# MSS_CTRL register map
Vendor: Texas Instruments
Registers are 32-bit, read-write, no defined reset value unless marked. A register's access mark holds for its fields unless they carry their own. Offsets are as the file gives them; [hi:lo] are bit positions; {n}, {i} and the like mark numbered series; 'fields as' and 'values as' point back to an identical list.

## MSS_CTRL (part 2 of 2)
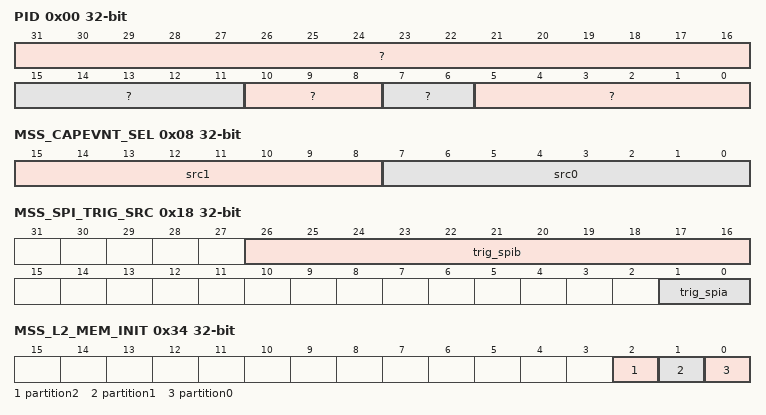
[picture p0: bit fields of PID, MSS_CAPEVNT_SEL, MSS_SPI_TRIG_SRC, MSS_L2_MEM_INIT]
0x00 PID ro
  [31:16] ?, [15:11] ?, [10:8] ?, [7:6] ?, [5:0] ?
0x04 MSS_SW_INT
  [4:0] pulse — Write_pulse bit field: writing 1'b1 to each bit will trigger MSS_SW_INT<0-4> respectively to CR5A/B.
0x08 MSS_CAPEVNT_SEL
  [15:8] src1 — Writing a value 'N' will select Nth interrupt from CR5A/B interrupt mapping to trigger CAP-EVENT1 to all MSS_RTIs. Example: writing 8'h0A will select 10th interrupt to trigger CAP-EVENT1 to all MSS_RTIs. (which is MSS_RTIB_INT1)
  [7:0] src0 — Writing a value 'N' will select Nth interrupt from CR5A/B interrupt mapping to trigger CAP-EVENT0 to all MSS_RTIs. Example: writing 8'h0A will select 10th interrupt to trigger CAP-EVENT0 to all MSS_RTIs. (which is MSS_RTIB_INT1)
0x0C MSS_DMA_REQ_SEL
  [31:0] select — Reserved for R&D. Do not touch
0x10 MSS_DMA1_REQ_SEL
  [31:0] select — Reserved for R&D. Do not touch
0x14 MSS_IRQ_REQ_SEL
  [31:0] select — Reserved for R&D. Do not touch
0x18 MSS_SPI_TRIG_SRC
  [26:16] trig_spib — Writing 1'b1 to each bit will trigger MSS_SPIB Trigger<0-10> respectively
  [1:0] trig_spia — RESERVED:Dont Touch
0x1C MSS_ATCM_MEM_INIT
  [0] mem_init — Write_pulse bit field: Writing 1'b1 will start initializing the ATCM banks of CR5A/B. Value in each row is initialized to 0x0C_0000_0000
0x20 MSS_ATCM_MEM_INIT_DONE
  [0] mem_init_done — This field will be high once initialization of ATCM banks is finished. Writing '1' would clear the bit.
0x24 MSS_ATCM_MEM_INIT_STATUS ro
  [0] mem_status — 1'b0: No initialization is happening for ATCM banks of CR5A/B 1'b1: Initialization is in progress for ATCM banks of CR5A/B
0x28 MSS_BTCM_MEM_INIT
  [0] mem_init — Write_pulse bit field: Writing 1'b1 will start initializing the B0/1TCM banks of CR5A/B
0x2C MSS_BTCM_MEM_INIT_DONE
  [0] mem_init_done — This field will be high once initialization of B0/1TCM banks is finished. Writing '1' would clear the bit.
0x30 MSS_BTCM_MEM_INIT_STATUS ro
  [0] mem_status — 1'b0: No initialization is happening for B0/1TCM banks of CR5A/B 1'b1: Initialization is in progress for B0/1TCM banks of CR5A/B
0x34 MSS_L2_MEM_INIT
  [2] partition2 — Write_pulse bit field: Writing 1'b1 will start initializing the L2 Bank2. Value in each row is initialized to 0x0
  [1] partition1 — Write_pulse bit field: Writing 1'b1 will start initializing the L2 Bank1. Value in each row is initialized to 0x0
  [0] partition0 — Write_pulse bit field: Writing 1'b1 will start initializing the L2 Bank0. Value in each row is initialized to 0x0
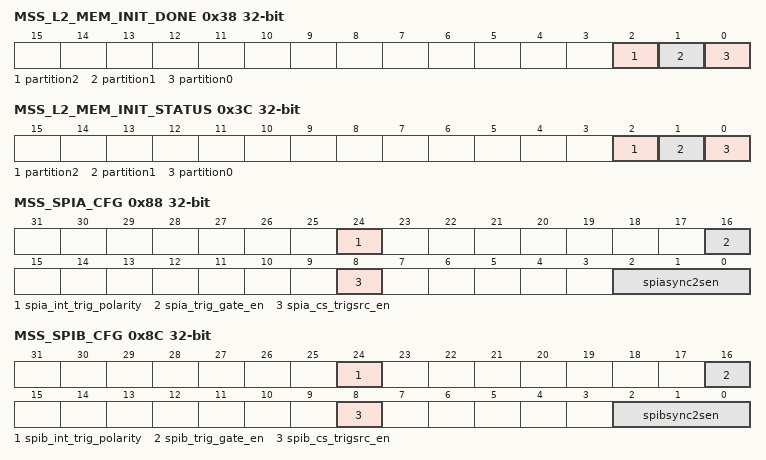
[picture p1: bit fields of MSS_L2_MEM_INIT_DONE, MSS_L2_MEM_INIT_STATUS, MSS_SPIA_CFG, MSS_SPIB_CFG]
0x38 MSS_L2_MEM_INIT_DONE
  [2] partition2 — This field will be high once intialization of L2 bank2 is finished. Writing '1' would clear the bit
  [1] partition1 — This field will be high once intialization of L2 bank1 is finished. Writing '1' would clear the bit
  [0] partition0 — This field will be high once intialization of L2 bank0 is finished. Writing '1' would clear the bit
0x3C MSS_L2_MEM_INIT_STATUS ro
  [2] partition2 — 1'b0: No initialization is happening for L2 bank2 1'b1: Initialization is in progress for L2 bank2
  [1] partition1 — 1'b0: No initialization is happening for L2 bank1 1'b1: Initialization is in progress for L2 bank1
  [0] partition0 — 1'b0: No initialization is happening for L2 bank0 1'b1: Initialization is in progress for L2 bank0
0x40 MSS_MAILBOX_MEM_INIT
  [0] mem0_init — Write_pulse bit field: Writing 1'b1 will start initializing the MSS_MBOX. Value in each row is initialized to 0x0
0x44 MSS_MAIlBOX_MEM_INIT_DONE
  [0] mem0_done — This field will be high once intialization of MSS_MBOX is finished. Writing '1' would clear the bit
0x48 MSS_MAILBOX_MEM_INIT_STATUS ro
  [0] mem0_status — 1'b0: No initialization is happening for MSS_MBOX 1'b1: Initialization is in progress for MSS_MBOX
0x4C MSS_RETRAM_MEM_INIT
  [0] mem0_init — Write_pulse bit field: Writing 1'b1 will start initializing the MSS_RETRAM. Value in each row is initialized to 0x0
0x50 MSS_RETRAM_MEM_INIT_DONE
  [0] mem0_done — This field will be high once intialization of MSS_RETRAM is finished. Writing '1' would clear the bit
0x54 MSS_RETRAM_MEM_INIT_STATUS ro
  [0] mem0_status — 1'b0: No initialization is happening for MSS_RETRAM 1'b1: Initialization is in progress for MSS_RETRAM
0x58 MSS_SPIA_MEM_INIT
  [0] mem0_init — RESERVED:Dont Touch
0x5C MSS_SPIA_MEM_INIT_DONE
  [0] mem0_done — RESERVED: Dont Use
0x60 MSS_SPIA_MEM_INIT_STATUS ro
  [0] mem0_status — RESERVED: Dont Use
0x64 MSS_SPIB_MEM_INIT
  [0] mem0_init — Write_pulse bit field: Writing 1'b1 will start initializing the MSS_SPIB. Value in each row is initialized to 0x0
0x68 MSS_SPIB_MEM_INIT_DONE
  [0] mem0_done — This field will be high once intialization of MSS_SPIB is finished. Writing '1' would clear the bit
0x6C MSS_SPIB_MEM_INIT_STATUS ro
  [0] mem0_status — 1'b0: No initialization is happening for MSS_SPIB 1'b1: Initialization is in progress for MSS_SPIB
0x70 MSS_TPCC_MEMINIT_START
  [0] tpcc_a_meminit_start — Write_pulse bit field: Writing 1'b1 will start initializing the MSS_TPCCA
0x74 MSS_TPCC_MEMINIT_DONE
  [0] tpcc_a_meminit_done — This field will be high once intialization of MSS_TPCCA is finished. Writing '1' would clear the bit
0x78 MSS_TPCC_MEMINIT_STATUS ro
  [0] tpcc_a_meminit_status — 1'b0: No initialization is happening for MSS_TPCCA 1'b1: Initialization is in progress for MSS_TPCCB
0x7C MSS_GPADC_MEM_INIT
  [0] mem0_init — Write_pulse bit field: Writing 1'b1 will start initializing the MSS_GPADC_DATA_MEM. Value in each row is initialized to 0x00_0000_03FF
0x80 MSS_GPADC_MEM_INIT_DONE
  [0] mem0_done — This field will be high once intialization of MSS_GPADC_DATA_MEM is finished. Writing '1' would clear the bit
0x84 MSS_GPADC_MEM_INIT_STATUS ro
  [0] mem0_status — 1'b0: No initialization is happening for MSS_GPADC_DATA_MEM 1'b1: Initialization is in progress for MSS_GPADC_DATA_MEM
0x88 MSS_SPIA_CFG — RESERVED: Dont Use
  [24] spia_int_trig_polarity — RESERVED:Dont Use
  [16] spia_trig_gate_en — RESERVED:Dont Use
  [8] spia_cs_trigsrc_en — RESERVED:Dont Use
  [2:0] spiasync2sen — RESERVED:Dont Use
0x8C MSS_SPIB_CFG
  [24] spib_int_trig_polarity — SPIB trigger source polarity select. 0 - Polarity 0, 1 -Polarity 1
  [16] spib_trig_gate_en — When set the TRIGGER s are un-gated only when chip-select is active
  [8] spib_cs_trigsrc_en — MIBSPIB CS Trigger SRC enable 1 : Use CS as trigger source
  [2:0] spibsync2sen — Donot touch the field. Used as Tie-off for IP-config.
0x90 MSS_EPWM_CFG
  [31:0] epwm_config — bit0: SW syncin for EPWM1 bit1: SW syncin for EPWM2 bit2: SW syncin for EPWM3 bit8:9 : select bits for EPWM1 '0' : external syncin '1' : reserved '2' : sw syncin '3' : reserved bit10:11 : select bits for EPWM2 '0' : external syncin '1' : chained from EPWM1 '2' : sw syncin '3' : reserved bit12:13 : select bits for EPWM3 '0' : external syncin '1' : chained from EPWM2 '2' : sw syncin '3' : reserved bit24:TBCLKEN for EPWM1 bit25:TBCLKEN for EPWM2 bit26:TBCLKEN for EPWM3
0x94 MSS_GIO_CFG
  [31:0] gio_config — bit0 : writing '1' will slect negedge for pulse generation of GIO_PAD_INT0 to IRQ bit1 : writing '1' will slect negedge for pulse generation of GIO_PAD_INT1to IRQ bit2: writing '1' will slect negedge for pulse generation of GIO_PAD_INT2 to IRQ bit3 : writing '1' will slect negedge for pulse generation of GIO_PAD_INT3 to IRQ bit4 : writing '1' will slect negedge for pulse generation of GIO_PAD_INT4 to IRQ bit5 : writing '1' will slect negedge for pulse generation of GIO_PAD_INT5 to IRQ bit6 : writing '1' will slect negedge for pulse generation of GIO_PAD_INT6 to IRQ bit7 : writing '1' will slect negedge for pulse generation of GIO_PAD_INT7 to IRQ
0x9C HW_SPARE_REG1
  [31:0] NU — Resereved for R&D
0xAC HW_SPARE_REG2
  [31:0] NU — Resereved for R&D
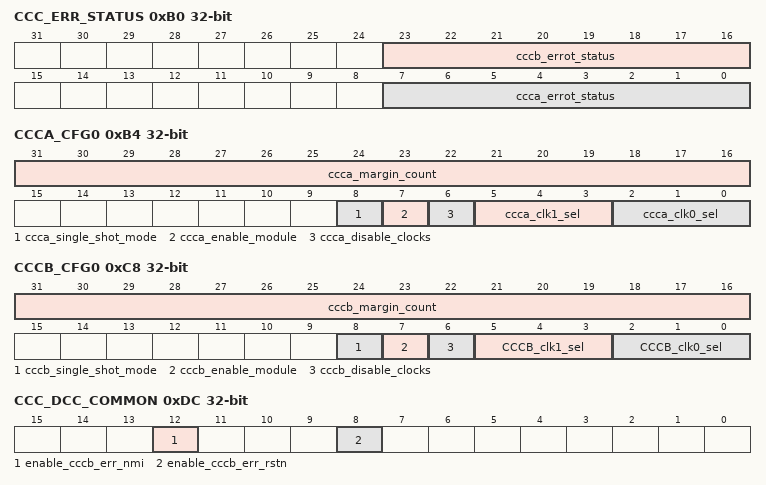
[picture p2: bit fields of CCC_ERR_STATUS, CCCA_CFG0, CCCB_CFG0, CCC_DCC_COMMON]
0xB0 CCC_ERR_STATUS ro
  [23:16] cccb_errot_status — CCCB Error Status (for Debug) {3'd0, counter_error, counter_done, timeout_error, counter_error, counter_done}
  [7:0] ccca_errot_status — CCCA Error Status (for Debug) {3'd0, counter_error, counter_done, timeout_error, counter_error, counter_done}
0xB4 CCCA_CFG0
  [31:16] ccca_margin_count — Margin value for clock comparison in terms of counter1 clock.CCC error will not be generated if counter1 counter value is within count1_expected_val +/- MARGIN_COUNT
  [8] ccca_single_shot_mode — 1: Single shot mode 0: Continuous mode
  [7] ccca_enable_module — 1'b1: Enables CCCA 1'b0: Disables CCCA
  [6] ccca_disable_clocks — 1: Clock gated to counter0 and counter1 0: Normal mode
  [5:3] ccca_clk1_sel — Selection for Clock 1 0: Select clock0_src0 as source for counter1 1: Select clock0_src1 as source for counter1 2: Select clock0_src2 as source for counter1 ... 7: Select clock0_src7 as source for counter1
  [2:0] ccca_clk0_sel — Selection for Clock 0 0: Select clock0_src0 as source for counter0 1: Select clock0_src1 as source for counter0 2: Select clock0_src2 as source for counter0 ... 7: Select clock0_src7 as source for counter0
0xB8 CCCA_CFG1
  [31:0] ccca_cfg — count0_expiry_val Counter 1 is compared for count1_expected_val +/- MARGIN_COUNT when counter0 expires after counting down from count0_expiry_val to 0
0xBC CCCA_CFG2
  [31:0] ccca_cfg — count1_expected_val Expected value of counter 1 when counter 0 expires after counting down from count0_expiry value
0xC0 CCCA_CFG3
  [31:0] ccca_cfg — Timeout Error Counter value in counter1 clock
0xC4 CCCA_CNTVAL ro
  [31:0] ccca_cfg — count1_val_out Real time value of counter1
0xC8 CCCB_CFG0
  [31:16] cccb_margin_count — Margin value for clock comparison in terms of counter1 clock.CCC error will not be generated if counter1 counter value is within count1_expected_val +/- MARGIN_COUNT
  [8] cccb_single_shot_mode — 1: Single shot mode 0: Continuous mode
  [7] cccb_enable_module — 1'b1: Enables CCCB 1'b0: Disables CCCB
  [6] cccb_disable_clocks — 1: Clock gated to counter0 and counter1 0: Normal mode
  [5:3] CCCB_clk1_sel — Selection for Clock 1 0: Select clock0_src0 as source for counter1 1: Select clock0_src1 as source for counter1 2: Select clock0_src2 as source for counter1 ... 7: Select clock0_src7 as source for counter1
  [2:0] CCCB_clk0_sel — Selection for Clock 0 0: Select clock0_src0 as source for counter0 1: Select clock0_src1 as source for counter0 2: Select clock0_src2 as source for counter0 ... 7: Select clock0_src7 as source for counter0
0xCC CCCB_CFG1
  [31:0] cccb_cfg — count0_expiry_val Counter 1 is compared for count1_expected_val +/- MARGIN_COUNT when counter0 expires after counting down from count0_expiry_val to 0
0xD0 CCCB_CFG2
  [31:0] cccb_cfg — count1_expected_val Expected value of counter 1 when counter 0 expires after counting down from count0_expiry value
0xD4 CCCB_CFG3
  [31:0] cccb_cfg — Timeout Error Counter value in counter1 clock
0xD8 CCCB_CNTVAL ro
  [31:0] cccb_cfg — count1_val_out Real time value of counter1
0xDC CCC_DCC_COMMON
  [12] enable_cccb_err_nmi — 1'b0:Enable CCCB error to generate NMI. 1'b1:disables CCCB error to generate NMI.
  [8] enable_cccb_err_rstn — 1'b0: Enable CCCB error to generate WD restn. 1'b1: disables CCCB error to generate WD restn.
0xE0 R5_GLOBAL_CONFIG
  [0] teinit — Exception handling state at reset. 0-ARM 1-Thumb
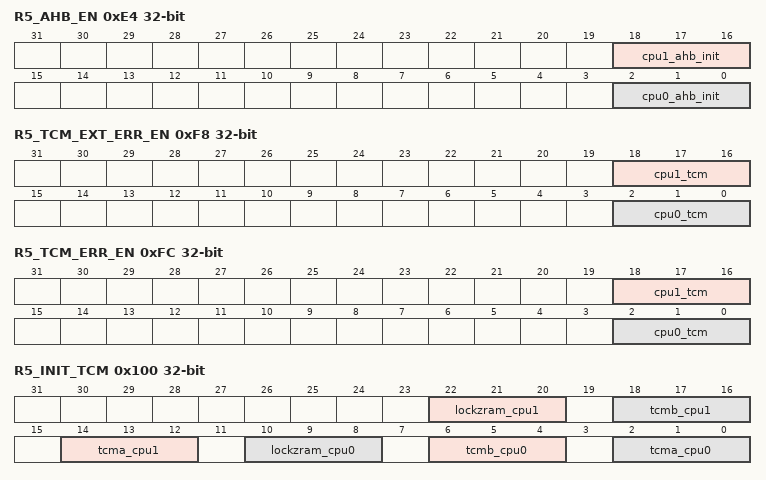
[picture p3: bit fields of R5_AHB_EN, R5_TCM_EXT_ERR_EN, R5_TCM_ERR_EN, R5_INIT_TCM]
0xE4 R5_AHB_EN
  [18:16] cpu1_ahb_init — Ti internal Register. Modifying this register is not recommended Signal decides whehter ahb interface is enabled or not.
  [2:0] cpu0_ahb_init — Ti internal Register. Modifying this register is not recommended Signal decides whehter ahb interface is enabled or not.
0xE8 R5A_AHB_BASE
  [19:0] ahb_base — Ti internal Register. Modifying this register is not recommended Decides the base address of ahb region
0xEC R5A_AHB_SIZE
  [4:0] ahb_size — Ti internal Register. Modifying this register is not recommended Code for selecting size for ahb. b00011 4KB b00100 8KB b00101 16KB b00110 32KB b00111 64KB b01000 128KB b01001 256KB b01010 512KB b01011 1MB b01100 2MB b01101 4MB b01110 8MB b01111 16MB b10000 32MB b10001 64MB b10010 128MB b10011 256MB b10100 512MB b10101 1GB b10110 2GB b10111 4GB
0xF0 R5B_AHB_BASE
  fields as R5A_AHB_BASE
0xF4 R5B_AHB_SIZE
  fields as R5A_AHB_SIZE
0xF8 R5_TCM_EXT_ERR_EN
  [18:16] cpu1_tcm — Ti internal Register. Modifying this register is not recommended TCMs external error enable. Tie each bit high to enable the external error signal for each TCM at reset
  [2:0] cpu0_tcm — Ti internal Register. Modifying this register is not recommended TCMs external error enable. Tie each bit high to enable the external error signal for each TCM at reset
0xFC R5_TCM_ERR_EN
  [18:16] cpu1_tcm — Ti internal Register. Modifying this register is not recommended TCMs ECC check enable. Tie each bit high to enable ECC checking on appropraite TCM
  [2:0] cpu0_tcm — Ti internal Register. Modifying this register is not recommended TCMs ECC check enable. Tie each bit high to enable ECC checking on appropraite TCM
0x100 R5_INIT_TCM
  [22:20] lockzram_cpu1 — Ti internal Register. Modifying this register is not recommended When HIGH ATCM base address at reset is 0x0 when LOW BTCM base address at reset is 0x0
  [18:16] tcmb_cpu1 — Ti internal Register. Modifying this register is not recommended When HIGH enables BTCM interface out of reset
  [14:12] tcma_cpu1 — Ti internal Register. Modifying this register is not recommended When HIGH enables ATCM interface out of reset
  [10:8] lockzram_cpu0 — Ti internal Register. Modifying this register is not recommended When HIGH ATCM base address at reset is 0x0 when LOW BTCM base address at reset is 0x0
  [6:4] tcmb_cpu0 — Ti internal Register. Modifying this register is not recommended When HIGH enables BTCM interface out of reset
  [2:0] tcma_cpu0 — Ti internal Register. Modifying this register is not recommended When HIGH enables ATCM interface out of reset
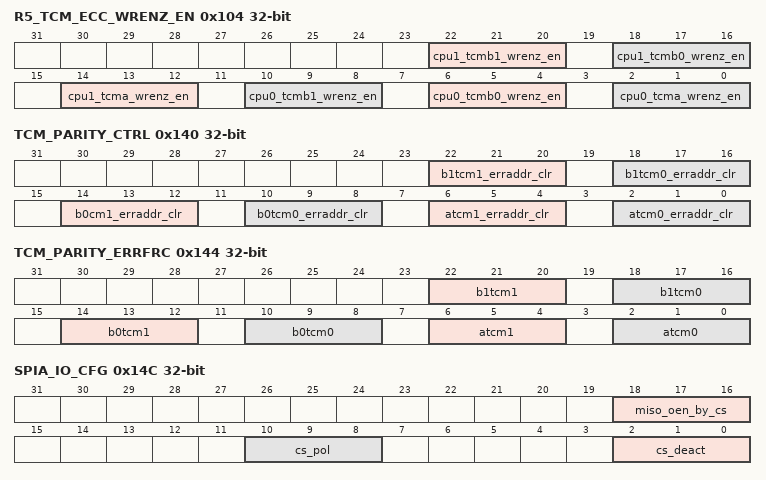
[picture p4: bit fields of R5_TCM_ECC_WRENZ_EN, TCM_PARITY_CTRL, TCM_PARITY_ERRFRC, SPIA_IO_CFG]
0x104 R5_TCM_ECC_WRENZ_EN
  [22:20] cpu1_tcmb1_wrenz_en — RESERVED: Dont Use
  [18:16] cpu1_tcmb0_wrenz_en — RESERVED: Dont Use
  [14:12] cpu1_tcma_wrenz_en — RESERVED: Dont Use
  [10:8] cpu0_tcmb1_wrenz_en — writing '000' blocks the writes to ECC-bits of TCMB0-RAM of CR5A. Writing '111' unblocks the writes to ECC-bits of TCMB1-RAM of CR5A
  [6:4] cpu0_tcmb0_wrenz_en — writing '000' blocks the writes to ECC-bits of TCMB0-RAM of CR5A. Writing '111' unblocks the writes to ECC-bits of TCMB0-RAM of CR5A
  [2:0] cpu0_tcma_wrenz_en — writing '000' blocks the writes to ECC-bits of TCMA-RAM of CR5A. Writing '111' unblocks the writes to ECC-bits of TCMA-RAM of CR5A
{0x108+4i} ESM_GATING{i} (i=0..3)
  [31:0] esm_gating — bit3:0 : writing '000' will ungate the ESM_GRP2_ERROR_{8i} bit7:4 : writing '000' will ungate the ESM_GRP2_ERROR_{8i+1} bit31:28 : writing '000' will ungate the ESM_GRP2_ERROR_{8i+7}
{0x108+4i} ESM_GATING{i} (i=4..7)
  [31:0] esm_gating — bit3:0 : writing '000' will ungate the ESM_GRP3_ERROR_{8i-32} bit7:4 : writing '000' will ungate the ESM_GRP3_ERROR_{8i-31} bit31:28 : writing '000' will ungate the ESM_GRP3_ERROR_{8i-25}
0x128 ERR_PARITY_ATCM0 ro
  [19:0] addr — Address lathched when parity error is occurred for ATCM of CR5A
0x12C ERR_PARITY_ATCM1 ro
  [19:0] addr — RESERVED: Dont Use
0x130 ERR_PARITY_B0TCM0 ro
  [19:0] addr — Address lathched when parity error is occurred for B0TCM of CR5A
0x134 ERR_PARITY_B0TCM1 ro
  [19:0] addr — RESERVED: Dont Use
0x138 ERR_PARITY_B1TCM0 ro
  [19:0] addr — Address lathched when parity error is occurred for B1TCM of CR5A
0x13C ERR_PARITY_B1TCM1 ro
  [19:0] addr — RESERVED: Dont Use
0x140 TCM_PARITY_CTRL
  [22:20] b1tcm1_erraddr_clr — RESERVED: Dont Use
  [18:16] b1tcm0_erraddr_clr — Write pulse bit field: writing 3'b111 clears the Address latched after parity error for B1TCM of CR5A
  [14:12] b0cm1_erraddr_clr — RESERVED: Dont Use
  [10:8] b0tcm0_erraddr_clr — RESERVED: Dont Use
  [6:4] atcm1_erraddr_clr — RESERVED: Dont Use
  [2:0] atcm0_erraddr_clr — Pulse bit-field writing 3'b111 clears the Address latched after parity error for ATCM of CR5A
0x144 TCM_PARITY_ERRFRC
  [22:20] b1tcm1 — RESERVED: Dont Use
  [18:16] b1tcm0 — Write pulse bit field: writing 3'b111 forces a parity error for B1TCM of CR5A
  [14:12] b0tcm1 — RESERVED: Dont Use
  [10:8] b0tcm0 — Write pulse bit field: writing 3'b111 forces a parity error for B0TCM of CR5A
  [6:4] atcm1 — RESERVED: Dont Use
  [2:0] atcm0 — Write pulse bit field: writing 3'b111 forces a parity error for ATCM of CR5A
0x148 HW_SPARE_REG3
  [31:0] NU — Resereved for R&D
0x14C SPIA_IO_CFG
  [18:16] miso_oen_by_cs — RESERVED:Dont Use
  [10:8] cs_pol — RESERVED:Dont Use
  [2:0] cs_deact — RESERVED:Dont Use
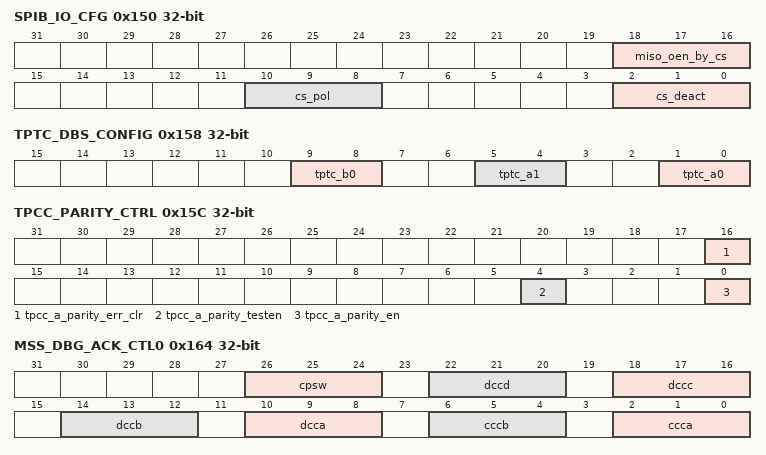
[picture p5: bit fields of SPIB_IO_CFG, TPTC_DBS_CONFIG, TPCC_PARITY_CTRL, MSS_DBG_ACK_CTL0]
0x150 SPIB_IO_CFG
  [18:16] miso_oen_by_cs — MIBSPIB MISO OE_N Control based on Chip selectCS-applicable in slave mode 1:MISO OEN controlled based on CS.When CS is inactive OE_N=1 0:MISO OEN controlled by IP
  [10:8] cs_pol — MIBSPIB CS polarity-slave mode 1: Active high 0:Active low
  [2:0] cs_deact — 1 : MIBSPIB External chip select is overridden with the value of MIBSPIB CS polarity-slave mode
0x154 SPI_HOST_IRQ
  [2:0] host_irq
0x158 TPTC_DBS_CONFIG
  [9:8] tptc_b0 — Default burst size tieoff value for TPTC_B0
  [5:4] tptc_a1 — Default burst size tieoff value for TPTC_A1
  [1:0] tptc_a0 — Default burst size tieoff value for TPTC_A0
0x15C TPCC_PARITY_CTRL
  [16] tpcc_a_parity_err_clr — Write pulse bit field: parity clear bit. Writing 1'b1 will clear the tpcc_a_parity_addr
  [4] tpcc_a_parity_testen — parity test enable for tpcc a
  [0] tpcc_a_parity_en — writing 1'b1 enables parity for TPCC_A
0x160 TPCC_PARITY_STATUS ro
  [7:0] tpcc_a_parity_addr — address where parity error happened for tpcca
0x164 MSS_DBG_ACK_CTL0
  [26:24] cpsw — Enable Suspend control for the peripheral. 0 :Peripheral not suspended along with processor 1: Peripehal Suspended along with procesor
  [22:20] dccd — Enable Suspend control for the peripheral. 0 :Peripheral not suspended along with processor 1: Peripehal Suspended along with procesor
  [18:16] dccc — Enable Suspend control for the peripheral. 0 :Peripheral not suspended along with processor 1: Peripehal Suspended along with procesor
  [14:12] dccb — Enable Suspend control for the peripheral. 0 :Peripheral not suspended along with processor 1: Peripehal Suspended along with procesor
  [10:8] dcca — Enable Suspend control for the peripheral. 0 :Peripheral not suspended along with processor 1: Peripehal Suspended along with procesor
  [6:4] cccb — Enable Suspend control for the peripheral. 0 :Peripheral not suspended along with processor 1: Peripehal Suspended along with procesor
  [2:0] ccca — Enable Suspend control for the peripheral. 0 :Peripheral not suspended along with processor 1: Peripehal Suspended along with procesor
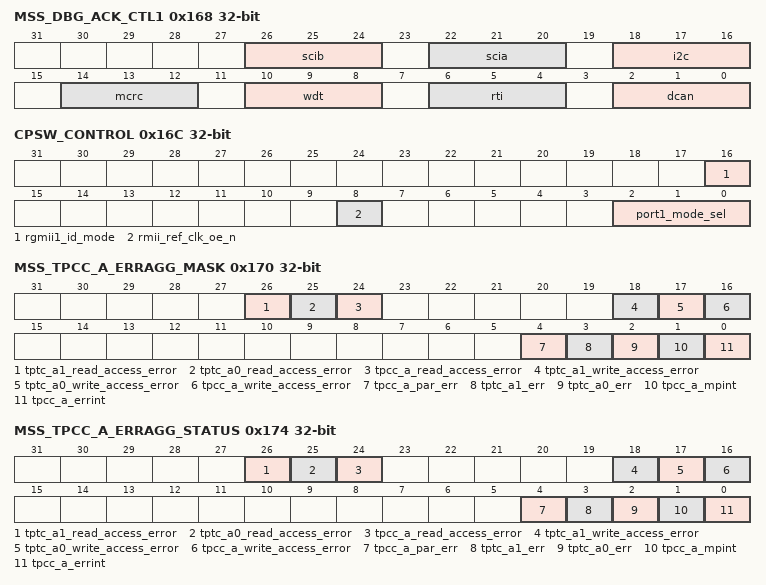
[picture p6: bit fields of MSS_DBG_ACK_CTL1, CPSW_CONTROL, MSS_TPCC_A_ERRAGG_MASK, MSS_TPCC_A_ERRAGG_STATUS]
0x168 MSS_DBG_ACK_CTL1
  [26:24] scib — Enable Suspend control for the peripheral. 0 :Peripheral not suspended along with processor 1: Peripehal Suspended along with procesor
  [22:20] scia — Enable Suspend control for the peripheral. 0 :Peripheral not suspended along with processor 1: Peripehal Suspended along with procesor
  [18:16] i2c — Enable Suspend control for the peripheral. 0 :Peripheral not suspended along with processor 1: Peripehal Suspended along with procesor
  [14:12] mcrc — Enable Suspend control for the peripheral. 0 :Peripheral not suspended along with processor 1: Peripehal Suspended along with procesor
  [10:8] wdt — Enable Suspend control for the peripheral. 0 :Peripheral not suspended along with processor 1: Peripehal Suspended along with procesor
  [6:4] rti — Enable Suspend control for the peripheral. 0 :Peripheral not suspended along with processor 1: Peripehal Suspended along with procesor
  [2:0] dcan — Enable Suspend control for the peripheral. 0 :Peripheral not suspended along with processor 1: Peripehal Suspended along with procesor
0x16C CPSW_CONTROL
  [16] rgmii1_id_mode — writing 1'b1 would disable the internal clock delays. And those delays need to be handled on board.
  [8] rmii_ref_clk_oe_n — To select the rmii_ref_clk from PAD or from MSS_RCM. 0: clock will be from mss_rcm through IO internal loopback 1: will be from
  [2:0] port1_mode_sel — Port 1 Interface 00 = GMII/MII 01 = RMII 10 = RGMII 11 = Not Supported
0x170 MSS_TPCC_A_ERRAGG_MASK
  [26] tptc_a1_read_access_error — Mask Error from MSS_TPTC_A1 to aggregated Error MSS_TPCC_A_ERRAGG 1 : Error is Masked 0 : Error is Unmasked
  [25] tptc_a0_read_access_error — Mask Error from MSS_TPTC_A0 to aggregated Error MSS_TPCC_A_ERRAGG 1 : Error is Masked 0 : Error is Unmasked
  [24] tpcc_a_read_access_error — Mask Error from MSS_TPCC_A to aggregated Error MSS_TPCC_A_ERRAGG 1 : Error is Masked 0 : Error is Unmasked
  [18] tptc_a1_write_access_error — Mask Error from MSS_TPTC_A1 to aggregated Error MSS_TPCC_A_ERRAGG 1 : Error is Masked 0 : Error is Unmasked
  [17] tptc_a0_write_access_error — Mask Error from MSS_TPTC_A0 to aggregated Error MSS_TPCC_A_ERRAGG 1 : Error is Masked 0 : Error is Unmasked
  [16] tpcc_a_write_access_error — Mask Error from MSS_TPCC_A to aggregated Error MSS_TPCC_A_ERRAGG 1 : Error is Masked 0 : Error is Unmasked
  [4] tpcc_a_par_err — Mask Error from MSS_TPCC_A to aggregated Error MSS_TPCC_A_ERRAGG 1 : Error is Masked 0 : Error is Unmasked
  [3] tptc_a1_err — Mask Error from MSS_TPTC_A1 to aggregated Error MSS_TPCC_A_ERRAGG 1 : Error is Masked 0 : Error is Unmasked
  [2] tptc_a0_err — Mask Error from MSS_TPTC_A0 to aggregated Error MSS_TPCC_A_ERRAGG 1 : Error is Masked 0 : Error is Unmasked
  [1] tpcc_a_mpint — Mask Error from MSS_TPCC_A to aggregated Error MSS_TPCC_A_ERRAGG 1 : Error is Masked 0 : Error is Unmasked
  [0] tpcc_a_errint — Mask Error from MSS_TPCC_A to aggregated Error MSS_TPCC_A_ERRAGG 1 : Error is Masked 0 : Error is Unmasked
0x174 MSS_TPCC_A_ERRAGG_STATUS
  [26] tptc_a1_read_access_error — Status of Error from MSS_TPTC_A1. Set only if Interupt is unmasked in MSS_TPCC_A_ERRAGG_MASK Wrie 0x1 to clear this Error.
  [25] tptc_a0_read_access_error — Status of Error from MSS_TPTC_A0. Set only if Interupt is unmasked in MSS_TPCC_A_ERRAGG_MASK Wrie 0x1 to clear this Error.
  [24] tpcc_a_read_access_error — Status of Error from MSS_TPCC_A. Set only if Interupt is unmasked in MSS_TPCC_A_ERRAGG_MASK Wrie 0x1 to clear this Error.
  [18] tptc_a1_write_access_error — Status of Error from MSS_TPTC_A1. Set only if Interupt is unmasked in MSS_TPCC_A_ERRAGG_MASK Wrie 0x1 to clear this Error.
  [17] tptc_a0_write_access_error — Status of Error from MSS_TPTC_A0. Set only if Interupt is unmasked in MSS_TPCC_A_ERRAGG_MASK Wrie 0x1 to clear this Error.
  [16] tpcc_a_write_access_error — Status of Error from MSS_TPCC_A. Set only if Interupt is unmasked in MSS_TPCC_A_ERRAGG_MASK Wrie 0x1 to clear this Error.
  [4] tpcc_a_par_err — Status of Error from MSS_TPCC_A. Set only if Interupt is unmasked in MSS_TPCC_A_ERRAGG_MASK Wrie 0x1 to clear this Error.
  [3] tptc_a1_err — Status of Error from MSS_TPTC_A1. Set only if Interupt is unmasked in MSS_TPCC_A_ERRAGG_MASK Wrie 0x1 to clear this Error.
  [2] tptc_a0_err — Status of Error from MSS_TPTC_A0. Set only if Interupt is unmasked in MSS_TPCC_A_ERRAGG_MASK Wrie 0x1 to clear this Error.
  [1] tpcc_a_mpint — Status of Error from MSS_TPCC_A. Set only if Interupt is unmasked in MSS_TPCC_A_ERRAGG_MASK Wrie 0x1 to clear this Error.
  [0] tpcc_a_errint — Status of Error from MSS_TPCC_A. Set only if Interupt is unmasked in MSS_TPCC_A_ERRAGG_MASK Wrie 0x1 to clear this Error.
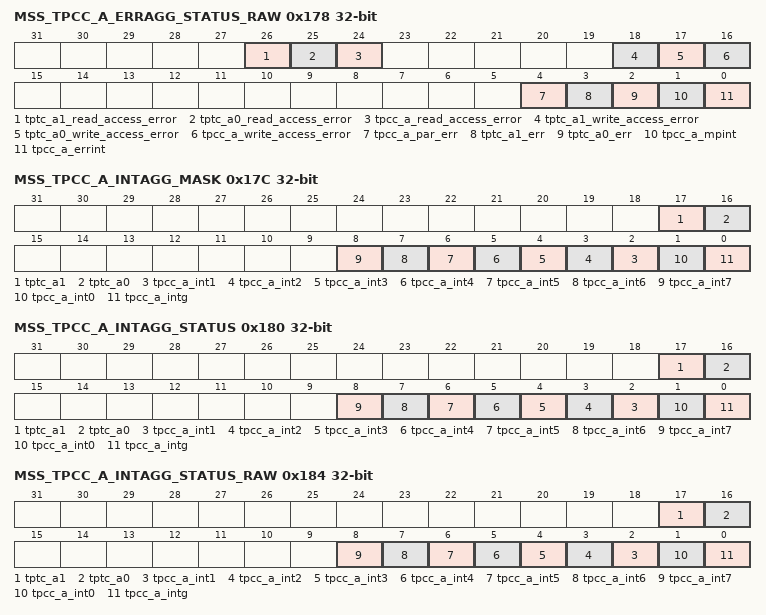
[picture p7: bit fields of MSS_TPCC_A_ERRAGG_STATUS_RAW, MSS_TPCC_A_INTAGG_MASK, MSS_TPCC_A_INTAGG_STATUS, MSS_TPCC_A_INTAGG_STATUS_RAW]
0x178 MSS_TPCC_A_ERRAGG_STATUS_RAW
  [26] tptc_a1_read_access_error — Raw Status of Error from MSS_TPTC_A1. Set irrespective if the Interupt is masked or unmasked in MSS_TPCC_A_ERRAGG_MASK
  [25] tptc_a0_read_access_error — Raw Status of Error from MSS_TPTC_A0. Set irrespective if the Interupt is masked or unmasked in MSS_TPCC_A_ERRAGG_MASK
  [24] tpcc_a_read_access_error — Raw Status of Error from MSS_TPCC_A. Set irrespective if the Interupt is masked or unmasked in MSS_TPCC_A_ERRAGG_MASK
  [18] tptc_a1_write_access_error — Raw Status of Error from MSS_TPTC_A1. Set irrespective if the Interupt is masked or unmasked in MSS_TPCC_A_ERRAGG_MASK
  [17] tptc_a0_write_access_error — Raw Status of Error from MSS_TPTC_A0. Set irrespective if the Interupt is masked or unmasked in MSS_TPCC_A_ERRAGG_MASK
  [16] tpcc_a_write_access_error — Raw Status of Error from MSS_TPCC_A. Set irrespective if the Interupt is masked or unmasked in MSS_TPCC_A_ERRAGG_MASK
  [4] tpcc_a_par_err — Raw Status of Error from MSS_TPCC_A. Set irrespective if the Interupt is masked or unmasked in MSS_TPCC_A_ERRAGG_MASK
  [3] tptc_a1_err — Raw Status of Error from MSS_TPTC_A1. Set irrespective if the Interupt is masked or unmasked in MSS_TPCC_A_ERRAGG_MASK
  [2] tptc_a0_err — Raw Status of Error from MSS_TPTC_A0. Set irrespective if the Interupt is masked or unmasked in MSS_TPCC_A_ERRAGG_MASK
  [1] tpcc_a_mpint — Raw Status of Error from MSS_TPCC_A. Set irrespective if the Interupt is masked or unmasked in MSS_TPCC_A_ERRAGG_MASK
  [0] tpcc_a_errint — Raw Status of Error from MSS_TPCC_A. Set irrespective if the Interupt is masked or unmasked in MSS_TPCC_A_ERRAGG_MASK
0x17C MSS_TPCC_A_INTAGG_MASK
  [17] tptc_a1 — Mask Interrupt from TPTC A1 to aggregated Interrupt MSS_TPCC_A_INTAGG 1 : Interrupt is Masked 0 : Interrupt is Unmasked
  [16] tptc_a0 — Mask Interrupt from TPTC A0 to aggregated Interrupt MSS_TPCC_A_INTAGG 1 : Interrupt is Masked 0 : Interrupt is Unmasked
  [n+1] tpcc_a_int{n} (n=1..7) — Mask Interrupt from MSS_TPCC_A to aggregated Interrupt MSS_TPCC_A_INTAGG 1 : Interrupt is Masked 0 : Interrupt is Unmasked
  [1] tpcc_a_int0 — Mask Interrupt from TPCC A to aggregated Interrupt MSS_TPCC_A_INTAGG 1 : Interrupt is Masked 0 : Interrupt is Unmasked
  [0] tpcc_a_intg — Mask Interrupt from MSS_TPCC_A to aggregated Interrupt MSS_TPCC_A_INTAGG 1 : Interrupt is Masked 0 : Interrupt is Unmasked
0x180 MSS_TPCC_A_INTAGG_STATUS
  [17] tptc_a1 — Status of Interrupt from TPTC A1. Set only if Interupt is unmasked in MSS_TPCC_A_INTAGG_MASK Wrie 0x1 to clear this interrupt.
  [16] tptc_a0 — Status of Interrupt from TPTC A0. Set only if Interupt is unmasked in MSS_TPCC_A_INTAGG_MASK Wrie 0x1 to clear this interrupt.
  [n+1] tpcc_a_int{n} (n=1..7) — Status of Interrupt from MSS_TPCC_A. Set only if Interupt is unmasked in MSS_TPCC_A_INTAGG_MASK Wrie 0x1 to clear this interrupt.
  [1] tpcc_a_int0 — Status of Interrupt from TPCC A Set only if Interupt is unmasked in MSS_TPCC_A_INTAGG_MASK Wrie 0x1 to clear this interrupt.
  [0] tpcc_a_intg — Status of Interrupt from MSS_TPCC_A. Set only if Interupt is unmasked in MSS_TPCC_A_INTAGG_MASK Wrie 0x1 to clear this interrupt.
0x184 MSS_TPCC_A_INTAGG_STATUS_RAW
  [17] tptc_a1 — Raw Status of Interrupt from TPTC A1. Set irrespective if the Interupt is masked or unmasked in MSS_TPCC_A_INTAGG_MASK
  [16] tptc_a0 — Raw Status of Interrupt from TPTC A0. Set irrespective if the Interupt is masked or unmasked in MSS_TPCC_A_INTAGG_MASK
  [n+1] tpcc_a_int{n} (n=1..7) — Raw Status of Interrupt from MSS_TPCC_A. Set irrespective if the Interupt is masked or unmasked in MSS_TPCC_C_INTAGG_MASK
  [1] tpcc_a_int0 — Raw Status of Interrupt from TPCC A. Set irrespective if the Interupt is masked or unmasked in MSS_TPCC_A_INTAGG_MASK
  [0] tpcc_a_intg — Raw Status of Interrupt from MSS_TPCC_A. Set irrespective if the Interupt is masked or unmasked in MSS_TPCC_C_INTAGG_MASK
0x1A0 MSS_BUS_SAFETY_CTRL
  [2:0] enable — Refer to TPR12 Substem Microarch document for more details
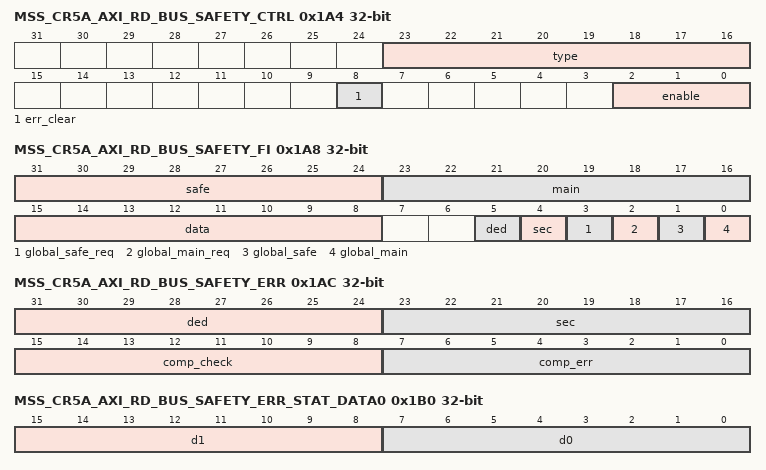
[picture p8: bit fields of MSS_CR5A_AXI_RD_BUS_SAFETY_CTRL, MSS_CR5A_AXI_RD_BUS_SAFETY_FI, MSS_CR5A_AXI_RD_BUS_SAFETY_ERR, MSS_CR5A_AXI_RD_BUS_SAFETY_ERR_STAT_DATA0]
0x1A4 MSS_CR5A_AXI_RD_BUS_SAFETY_CTRL access per field
  [23:16] type ro — Refer to TPR12 Substem Microarch document for more details
  [8] err_clear rw — Refer to TPR12 Substem Microarch document for more details
  [2:0] enable rw — Refer to TPR12 Substem Microarch document for more details
0x1A8 MSS_CR5A_AXI_RD_BUS_SAFETY_FI
  [31:24] safe — Refer to TPR12 Substem Microarch document for more details
  [23:16] main — Refer to TPR12 Substem Microarch document for more details
  [15:8] data — Refer to TPR12 Substem Microarch document for more details
  [5] ded — Refer to TPR12 Substem Microarch document for more details
  [4] sec — Refer to TPR12 Substem Microarch document for more details
  [3] global_safe_req — Refer to TPR12 Substem Microarch document for more details
  [2] global_main_req — Refer to TPR12 Substem Microarch document for more details
  [1] global_safe — Refer to TPR12 Substem Microarch document for more details
  [0] global_main — Refer to TPR12 Substem Microarch document for more details
0x1AC MSS_CR5A_AXI_RD_BUS_SAFETY_ERR ro
  [31:24] ded — Refer to TPR12 Substem Microarch document for more details
  [23:16] sec — Refer to TPR12 Substem Microarch document for more details
  [15:8] comp_check — Refer to TPR12 Substem Microarch document for more details
  [7:0] comp_err — Refer to TPR12 Substem Microarch document for more details
0x1B0 MSS_CR5A_AXI_RD_BUS_SAFETY_ERR_STAT_DATA0 ro
  [15:8] d1 — Refer to TPR12 Substem Microarch document for more details
  [7:0] d0 — Refer to TPR12 Substem Microarch document for more details
0x1B4 MSS_CR5A_AXI_RD_BUS_SAFETY_ERR_STAT_CMD ro
  [31:0] stat — Refer to TPR12 Substem Microarch document for more details
0x1B8 MSS_CR5A_AXI_RD_BUS_SAFETY_ERR_STAT_READ ro
  fields as MSS_CR5A_AXI_RD_BUS_SAFETY_ERR_STAT_CMD
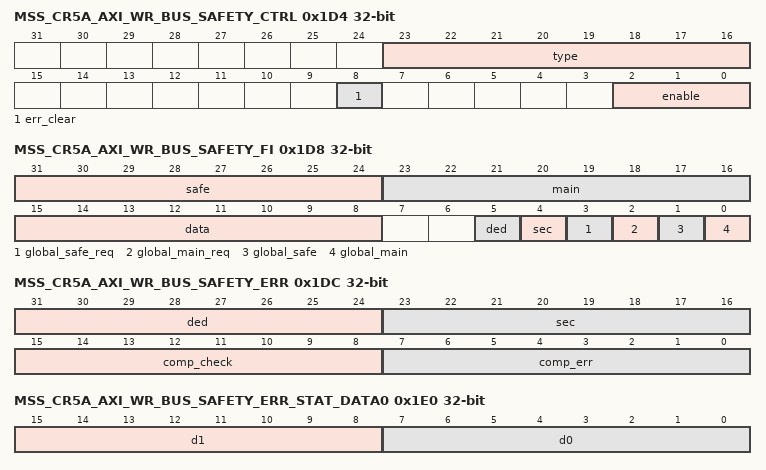
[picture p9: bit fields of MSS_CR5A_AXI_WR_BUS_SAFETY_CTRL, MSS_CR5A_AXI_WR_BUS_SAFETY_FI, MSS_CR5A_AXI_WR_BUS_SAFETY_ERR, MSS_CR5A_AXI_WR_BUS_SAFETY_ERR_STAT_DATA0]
0x1D4 MSS_CR5A_AXI_WR_BUS_SAFETY_CTRL access per field
  fields as MSS_CR5A_AXI_RD_BUS_SAFETY_CTRL
0x1D8 MSS_CR5A_AXI_WR_BUS_SAFETY_FI
  fields as MSS_CR5A_AXI_RD_BUS_SAFETY_FI
0x1DC MSS_CR5A_AXI_WR_BUS_SAFETY_ERR ro
  fields as MSS_CR5A_AXI_RD_BUS_SAFETY_ERR
0x1E0 MSS_CR5A_AXI_WR_BUS_SAFETY_ERR_STAT_DATA0 ro
  fields as MSS_CR5A_AXI_RD_BUS_SAFETY_ERR_STAT_DATA0
0x1E4 MSS_CR5A_AXI_WR_BUS_SAFETY_ERR_STAT_CMD ro
  fields as MSS_CR5A_AXI_RD_BUS_SAFETY_ERR_STAT_CMD
0x1E8 MSS_CR5A_AXI_WR_BUS_SAFETY_ERR_STAT_WRITE ro
  fields as MSS_CR5A_AXI_RD_BUS_SAFETY_ERR_STAT_CMD
0x1EC MSS_CR5A_AXI_WR_BUS_SAFETY_ERR_STAT_WRITERESP ro
  fields as MSS_CR5A_AXI_RD_BUS_SAFETY_ERR_STAT_CMD
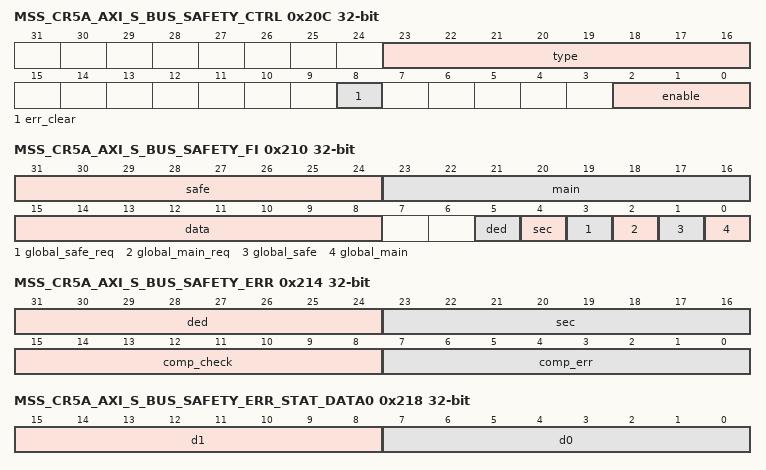
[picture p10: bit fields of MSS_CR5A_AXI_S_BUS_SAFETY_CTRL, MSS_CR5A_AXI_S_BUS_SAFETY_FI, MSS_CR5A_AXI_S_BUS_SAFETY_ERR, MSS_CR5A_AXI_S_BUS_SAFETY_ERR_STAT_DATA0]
0x20C MSS_CR5A_AXI_S_BUS_SAFETY_CTRL access per field
  fields as MSS_CR5A_AXI_RD_BUS_SAFETY_CTRL
0x210 MSS_CR5A_AXI_S_BUS_SAFETY_FI
  fields as MSS_CR5A_AXI_RD_BUS_SAFETY_FI
0x214 MSS_CR5A_AXI_S_BUS_SAFETY_ERR ro
  fields as MSS_CR5A_AXI_RD_BUS_SAFETY_ERR
0x218 MSS_CR5A_AXI_S_BUS_SAFETY_ERR_STAT_DATA0 ro
  fields as MSS_CR5A_AXI_RD_BUS_SAFETY_ERR_STAT_DATA0
0x21C MSS_CR5A_AXI_S_BUS_SAFETY_ERR_STAT_CMD ro
  fields as MSS_CR5A_AXI_RD_BUS_SAFETY_ERR_STAT_CMD
0x220 MSS_CR5A_AXI_S_BUS_SAFETY_ERR_STAT_WRITE ro
  fields as MSS_CR5A_AXI_RD_BUS_SAFETY_ERR_STAT_CMD
0x224 MSS_CR5A_AXI_S_BUS_SAFETY_ERR_STAT_READ ro
  fields as MSS_CR5A_AXI_RD_BUS_SAFETY_ERR_STAT_CMD
0x228 MSS_CR5A_AXI_S_BUS_SAFETY_ERR_STAT_WRITERESP ro
  fields as MSS_CR5A_AXI_RD_BUS_SAFETY_ERR_STAT_CMD
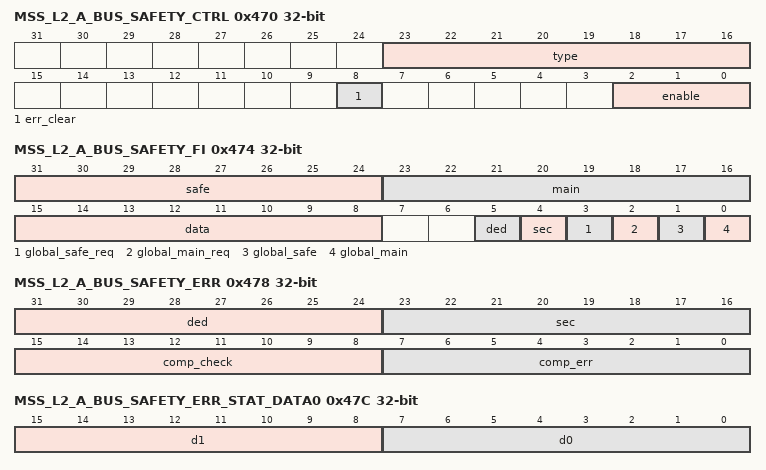
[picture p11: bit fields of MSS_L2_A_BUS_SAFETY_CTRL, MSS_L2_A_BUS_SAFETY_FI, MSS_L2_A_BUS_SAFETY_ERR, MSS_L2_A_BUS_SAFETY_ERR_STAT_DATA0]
0x470 MSS_L2_A_BUS_SAFETY_CTRL access per field
  fields as MSS_CR5A_AXI_RD_BUS_SAFETY_CTRL
0x474 MSS_L2_A_BUS_SAFETY_FI
  fields as MSS_CR5A_AXI_RD_BUS_SAFETY_FI
0x478 MSS_L2_A_BUS_SAFETY_ERR ro
  fields as MSS_CR5A_AXI_RD_BUS_SAFETY_ERR
0x47C MSS_L2_A_BUS_SAFETY_ERR_STAT_DATA0 ro
  fields as MSS_CR5A_AXI_RD_BUS_SAFETY_ERR_STAT_DATA0
0x480 MSS_L2_A_BUS_SAFETY_ERR_STAT_CMD ro
  fields as MSS_CR5A_AXI_RD_BUS_SAFETY_ERR_STAT_CMD
0x484 MSS_L2_A_BUS_SAFETY_ERR_STAT_WRITE ro
  fields as MSS_CR5A_AXI_RD_BUS_SAFETY_ERR_STAT_CMD
0x488 MSS_L2_A_BUS_SAFETY_ERR_STAT_READ ro
  fields as MSS_CR5A_AXI_RD_BUS_SAFETY_ERR_STAT_CMD
0x48C MSS_L2_A_BUS_SAFETY_ERR_STAT_WRITERESP ro
  fields as MSS_CR5A_AXI_RD_BUS_SAFETY_ERR_STAT_CMD
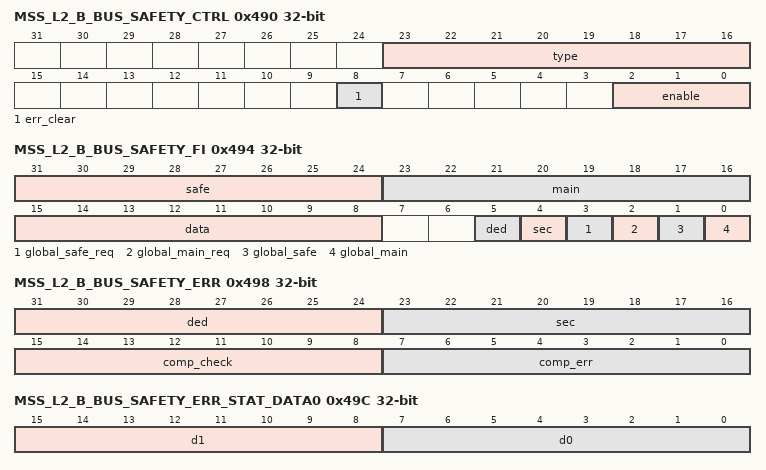
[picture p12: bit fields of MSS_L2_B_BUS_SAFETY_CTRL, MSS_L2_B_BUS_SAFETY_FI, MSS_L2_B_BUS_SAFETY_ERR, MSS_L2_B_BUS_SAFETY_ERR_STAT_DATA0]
0x490 MSS_L2_B_BUS_SAFETY_CTRL access per field
  fields as MSS_CR5A_AXI_RD_BUS_SAFETY_CTRL
0x494 MSS_L2_B_BUS_SAFETY_FI
  fields as MSS_CR5A_AXI_RD_BUS_SAFETY_FI
0x498 MSS_L2_B_BUS_SAFETY_ERR ro
  fields as MSS_CR5A_AXI_RD_BUS_SAFETY_ERR
0x49C MSS_L2_B_BUS_SAFETY_ERR_STAT_DATA0 ro
  fields as MSS_CR5A_AXI_RD_BUS_SAFETY_ERR_STAT_DATA0
0x4A0 MSS_L2_B_BUS_SAFETY_ERR_STAT_CMD ro
  fields as MSS_CR5A_AXI_RD_BUS_SAFETY_ERR_STAT_CMD
0x4A4 MSS_L2_B_BUS_SAFETY_ERR_STAT_WRITE ro
  fields as MSS_CR5A_AXI_RD_BUS_SAFETY_ERR_STAT_CMD
0x4A8 MSS_L2_B_BUS_SAFETY_ERR_STAT_READ ro
  fields as MSS_CR5A_AXI_RD_BUS_SAFETY_ERR_STAT_CMD
0x4AC MSS_L2_B_BUS_SAFETY_ERR_STAT_WRITERESP ro
  fields as MSS_CR5A_AXI_RD_BUS_SAFETY_ERR_STAT_CMD
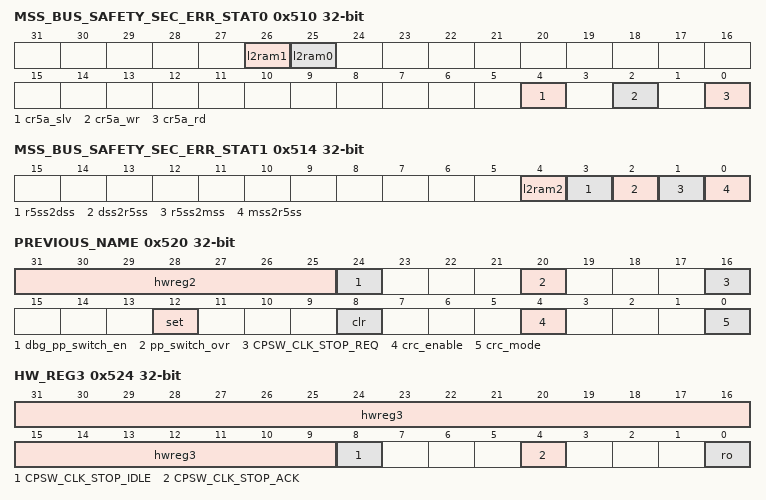
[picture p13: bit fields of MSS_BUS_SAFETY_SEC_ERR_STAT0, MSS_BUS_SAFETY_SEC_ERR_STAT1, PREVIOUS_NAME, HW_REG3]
0x510 MSS_BUS_SAFETY_SEC_ERR_STAT0 ro
  [26] l2ram1 — Bus safety single-bit-error of Node mentioned in the field
  [25] l2ram0 — Bus safety single-bit-error of Node mentioned in the field
  [4] cr5a_slv — Bus safety single-bit-error of Node mentioned in the field
  [2] cr5a_wr — Bus safety single-bit-error of Node mentioned in the field
  [0] cr5a_rd — Bus safety single-bit-error of Node mentioned in the field
0x514 MSS_BUS_SAFETY_SEC_ERR_STAT1 ro
  [4] l2ram2 — Bus safety single-bit-error of Node mentioned in the field
  [3] r5ss2dss — Bus safety single-bit-error of Node mentioned in the field
  [2] dss2r5ss — Bus safety single-bit-error of Node mentioned in the field
  [1] r5ss2mss — Bus safety single-bit-error of Node mentioned in the field
  [0] mss2r5ss — Bus safety single-bit-error of Node mentioned in the field
0x518 HW_REG0
  [31:0] hwreg0 — HW reserved Regsiter
0x51C HW_REG1
  [31:0] hwreg1 — HW reserved Regsiter
0x520 PREVIOUS_NAME
  [31:25] hwreg2 — HW reserved Register
  [24] dbg_pp_switch_en — Writing 1'b1 will allow CPSW ping-pong switch to happen during debugger reads (through JTAG).
  [20] pp_switch_ovr — Writing 1'b1 takes override on the CPWS ping-pong switch.Ping-pong switch doesn t happen even after reading the configured end-address.
  [16] CPSW_CLK_STOP_REQ — CPSW clock stop req
  [12] set — Write pulse bit field: Write 1'b1 whenever ping_pong_sel needs to be set.
  [8] clr — Write pulse bit field: Write 1'b1 whenever ping_pong_sel needs to be cleared.
  [4] crc_enable — 1'b0: CRC disable 1'b1: CRC enable
  [0] crc_mode — 1'b0 : CRC16CCITT 1'b1 : ETHERNET CRC32
0x524 HW_REG3 ro
  [31:9] hwreg3 — HW reserved Register
  [8] CPSW_CLK_STOP_IDLE — CPSW clock stop idle
  [4] CPSW_CLK_STOP_ACK — CPSW clock stop ack
  [0] ro — This denotes the status of ping_pong_sel bit.
0x528 HW_REG4
  [31:0] mss_pcrA_timeout_cfg — Configures the timeout value for MSS_PCRA.
{0x518+4i} HW_REG{i} (i=5..7)
  [31:0] hwreg{i} — HW reserved Register
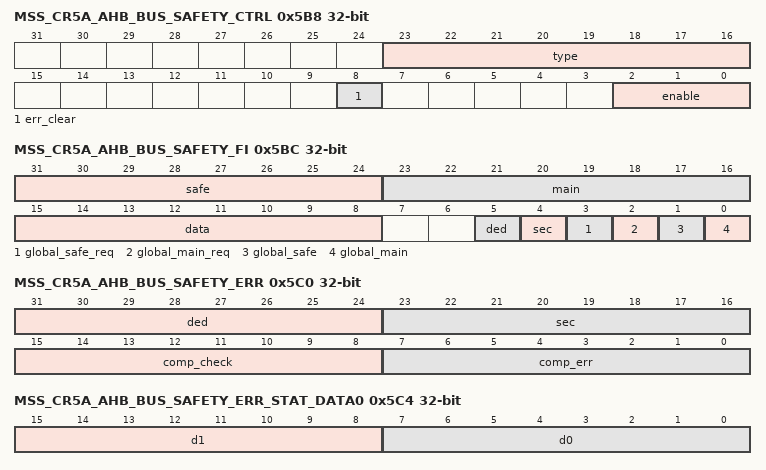
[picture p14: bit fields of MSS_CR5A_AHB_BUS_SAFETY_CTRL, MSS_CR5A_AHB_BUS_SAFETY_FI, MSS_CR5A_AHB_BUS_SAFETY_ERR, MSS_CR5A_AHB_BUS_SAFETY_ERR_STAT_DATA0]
0x5B8 MSS_CR5A_AHB_BUS_SAFETY_CTRL access per field
  fields as MSS_CR5A_AXI_RD_BUS_SAFETY_CTRL
0x5BC MSS_CR5A_AHB_BUS_SAFETY_FI
  fields as MSS_CR5A_AXI_RD_BUS_SAFETY_FI
0x5C0 MSS_CR5A_AHB_BUS_SAFETY_ERR ro
  fields as MSS_CR5A_AXI_RD_BUS_SAFETY_ERR
0x5C4 MSS_CR5A_AHB_BUS_SAFETY_ERR_STAT_DATA0 ro
  fields as MSS_CR5A_AXI_RD_BUS_SAFETY_ERR_STAT_DATA0
0x5C8 MSS_CR5A_AHB_BUS_SAFETY_ERR_STAT_CMD ro
  fields as MSS_CR5A_AXI_RD_BUS_SAFETY_ERR_STAT_CMD
0x5CC MSS_CR5A_AHB_BUS_SAFETY_ERR_STAT_WRITE ro
  fields as MSS_CR5A_AXI_RD_BUS_SAFETY_ERR_STAT_CMD
0x5D0 MSS_CR5A_AHB_BUS_SAFETY_ERR_STAT_READ ro
  fields as MSS_CR5A_AXI_RD_BUS_SAFETY_ERR_STAT_CMD
0x5D4 MSS_CR5A_AHB_BUS_SAFETY_ERR_STAT_WRITERESP ro
  fields as MSS_CR5A_AXI_RD_BUS_SAFETY_ERR_STAT_CMD
0x5F8 DMM_CTRL_REG
  [0] dmm_pad_select — 0: SOC will be able to send the packet to DMMA/B 1: PAD will be able to send the packet to DMMA/B controlling from PAD
0x5FC MSS_CR5A_MBOX_WRITE_DONE
  [4n] proc_{n} (n=0..7) — Write pulse bit field: This register should be written once finishing writing into the mailbox memory of processor {n}
0x600 MSS_CR5A_MBOX_READ_REQ
  [4n] proc_{n} (n=0..7) — This is request from processor {n} to mss_cr5a. Requesting it to read from mailbox.
0x604 MSS_CR5A_MBOX_READ_DONE
  [4n] proc_{n} (n=0..7) — This register should be written once finishing reading from CR5A's mailbox written by proc {n}
0x614 MSS_PBIST_KEY_RST
  [7:4] pbist_st_rst — MSS PBIST controller will be brought out of reset when value is 0xA
  [3:0] pbist_st_key — Top PBIST Selftest Key. Valid value is 0x5
{0x618+4i} MSS_PBIST_REG{i} (i=0..2)
  [31:0] pbist_reg
0x624 MSS_QSPI_CONFIG
  [10:8] clk_loopback — Write 3'b111 to take board level loop back clock for QSPI
  [2:0] ext_clk — Write 3'b111 to external clock as QSPI baud clock source needed for DFT IO char.
0x628 MSS_STC_CONTROL
  [2:0] cr5_wfi_overide — writing 3'b111 will bypass the wfi signals from R5SS.
0x62C MSS_CTI_TRIG_SEL
  [7:0] trig8_sel — Used for selecting the trigger source for 8th trigger of MSS_CTI
0x630 MSS_DBGSS_CTI_TRIG_SEL
  [23:16] trig3 — Used for selecting the trigger source for 3rd trigger of ONE_MCU_CTI
  [15:8] trig2 — Used for selecting the trigger source for 2nd trigger of ONE_MCU_CTI
  [7:0] trig1 — Used for selecting the trigger source for 1st trigger of ONE_MCU_CTI
{0x634+4i} MSS_BOOT_INFO_REG{i} (i=0..7)
  [31:0] config — Reserved Register for Software use
0x654 MSS_TPTC_ECCAGGR_CLK_CNTRL
  [2] tptc_B0 — Writing '0' will gate the clock to TPTC_B0-FIFO during ECC-AGGR interaction(fault injection)
  [1] tptc_A1 — Writing '0' will gate the clock to TPTC_A1-FIFO during ECC-AGGR interaction(fault injection)
  [0] tptc_A0 — Writing '0' will gate the clock to TPTC_A0-FIFO during ECC-AGGR interaction(fault injection)
